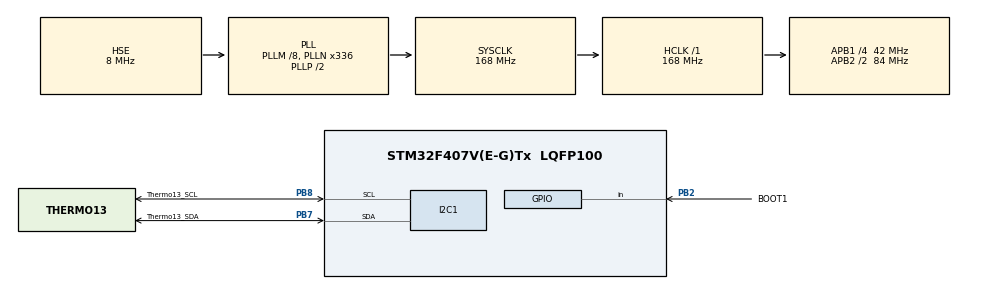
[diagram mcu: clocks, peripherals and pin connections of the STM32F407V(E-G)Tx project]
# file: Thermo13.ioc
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Mcu.Family=STM32F4
Mcu.Name=STM32F407V(E-G)Tx
Mcu.Package=LQFP100
NVIC.I2C1_ER_IRQn=true\:0\:0\:false\:false\:true\:true\:true\:true
NVIC.I2C1_EV_IRQn=true\:0\:0\:false\:false\:true\:true\:true\:true
NVIC.PriorityGroup=NVIC_PRIORITYGROUP_0
PA13.GPIO_Label=SWDIO
PA13.Mode=JTAG_5_pins
PA13.Signal=SYS_JTMS-SWDIO
PA14.GPIO_Label=SWCLK
PA14.Mode=JTAG_5_pins
PA14.Signal=SYS_JTCK-SWCLK
PA15.Mode=JTAG_5_pins
PA15.Signal=SYS_JTDI
PB2.GPIO_Label=BOOT1
PB2.GPIO_Mode=GPIO_MODE_INPUT
PB2.GPIO_PuPd=GPIO_NOPULL
PB2.Signal=GPIO_Input
PB3.Mode=JTAG_5_pins
PB3.Signal=SYS_JTDO-SWO
PB4.Mode=JTAG_5_pins
PB4.Signal=SYS_JTRST
PB7.GPIO_Label=Thermo13_SDA
PB7.Mode=I2C
PB7.Signal=I2C1_SDA
PB8.GPIO_Label=Thermo13_SCL
PB8.Mode=I2C
PB8.Signal=I2C1_SCL
PC14-OSC32_IN.GPIO_Label=PC14-OSC32_IN
PC14-OSC32_IN.Mode=LSE-External-Oscillator
PC14-OSC32_IN.Signal=RCC_OSC32_IN
PC15-OSC32_OUT.GPIO_Label=PC15-OSC32_OUT
PC15-OSC32_OUT.Mode=LSE-External-Oscillator
PC15-OSC32_OUT.Signal=RCC_OSC32_OUT
PH0-OSC_IN.GPIO_Label=PH0-OSC_IN
PH0-OSC_IN.Mode=HSE-External-Oscillator
PH0-OSC_IN.Signal=RCC_OSC_IN
PH1-OSC_OUT.GPIO_Label=PH1-OSC_OUT
PH1-OSC_OUT.Mode=HSE-External-Oscillator
PH1-OSC_OUT.Signal=RCC_OSC_OUT
ProjectManager.HeapSize=0x200
ProjectManager.StackSize=0x400
ProjectManager.TargetToolchain=STM32CubeIDE
RCC.48MHZClocksFreq_Value=48000000
RCC.AHBFreq_Value=168000000
RCC.APB1CLKDivider=RCC_HCLK_DIV4
RCC.APB1Freq_Value=42000000
RCC.APB1TimFreq_Value=84000000
RCC.APB2CLKDivider=RCC_HCLK_DIV2
RCC.APB2Freq_Value=84000000
RCC.APB2TimFreq_Value=168000000
RCC.CortexFreq_Value=168000000
RCC.HCLKFreq_Value=168000000
RCC.HSE_VALUE=8000000
RCC.HSI_VALUE=16000000
RCC.PLLM=8
RCC.PLLN=336
RCC.PLLQ=7
RCC.PLLSourceVirtual=RCC_PLLSOURCE_HSE
RCC.SYSCLKFreq_VALUE=168000000
RCC.SYSCLKSource=RCC_SYSCLKSOURCE_PLLCLK
RCC.VCOOutputFreq_Value=336000000
board=STM32F407G-DISC1

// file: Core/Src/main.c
/* USER CODE BEGIN Header */
/**
  ******************************************************************************
  * @file           : main.c
  * @brief          : Main program body
  ******************************************************************************
  * @attention
  *
  * Copyright (c) 2023 STMicroelectronics.
  * All rights reserved.
  *
  * This software is licensed under terms that can be found in the LICENSE file
  * in the root directory of this software component.
  * If no LICENSE file comes with this software, it is provided AS-IS.
  *
  ******************************************************************************
  */
/* USER CODE END Header */
#include "main.h"

/* USER CODE BEGIN Includes */
#include <stdio.h>
#include <stdint.h>
#include "Thermo13.h"
/* USER CODE END Includes */

/* USER CODE BEGIN PD */
#define THERMO_SLAVE_ADDR (0x48 << 1)
/* USER CODE END PD */

I2C_HandleTypeDef hi2c1;

void SystemClock_Config(void);
static void MX_GPIO_Init(void);
static void MX_I2C1_Init(void);

/* USER CODE BEGIN 0 */
int _write(int file, char *ptr, int len)

{
	int DataIdx;

    for(DataIdx = 0; DataIdx < len; DataIdx++)

    { ITM_SendChar(*ptr++); }

     return len;

}
/* USER CODE END 0 */

int main(void)
{
  /* USER CODE BEGIN 1 */
uint8_t buf[2];
char log[100];;
float temperature;
  /* USER CODE END 1 */

  /* MCU Configuration--------------------------------------------------------*/

  /* Reset of all peripherals, Initializes the Flash interface and the Systick. */
  HAL_Init();

  /* Configure the system clock */
  SystemClock_Config();

  /* Initialize all configured peripherals */
  MX_GPIO_Init();
  MX_I2C1_Init();

  /* Infinite loop */
  /* USER CODE BEGIN WHILE */
  while (1)
  {
	  HAL_I2C_Master_Receive(&hi2c1, THERMO_SLAVE_ADDR, buf, sizeof(buf), HAL_MAX_DELAY);
	  sprintf(log, "I2C Slave Data: 0x%x, 0x%x,\r\n", buf[0], buf[1]);
	  printf(log);
	  log[0] = '\0';
	  temperature = calc_temp(buf);
	  printf("Converted Data\r\n");
	  sprintf(log, " %.1f deg C\r\n",temperature);
	  printf(log);
	  HAL_Delay(1000);
  }

    /* USER CODE END WHILE */

}

void SystemClock_Config(void)
{
  RCC_OscInitTypeDef RCC_OscInitStruct = {0};
  RCC_ClkInitTypeDef RCC_ClkInitStruct = {0};

  /** Configure the main internal regulator output voltage
  */
  __HAL_RCC_PWR_CLK_ENABLE();
  __HAL_PWR_VOLTAGESCALING_CONFIG(PWR_REGULATOR_VOLTAGE_SCALE1);

  /** Initializes the RCC Oscillators according to the specified parameters
  * in the RCC_OscInitTypeDef structure.
  */
  RCC_OscInitStruct.OscillatorType = RCC_OSCILLATORTYPE_HSE;
  RCC_OscInitStruct.HSEState = RCC_HSE_ON;
  RCC_OscInitStruct.PLL.PLLState = RCC_PLL_ON;
  RCC_OscInitStruct.PLL.PLLSource = RCC_PLLSOURCE_HSE;
  RCC_OscInitStruct.PLL.PLLM = 8;
  RCC_OscInitStruct.PLL.PLLN = 336;
  RCC_OscInitStruct.PLL.PLLP = RCC_PLLP_DIV2;
  RCC_OscInitStruct.PLL.PLLQ = 7;
  if (HAL_RCC_OscConfig(&RCC_OscInitStruct) != HAL_OK)
  {
    Error_Handler();
  }

  /** Initializes the CPU, AHB and APB buses clocks
  */
  RCC_ClkInitStruct.ClockType = RCC_CLOCKTYPE_HCLK|RCC_CLOCKTYPE_SYSCLK
                              |RCC_CLOCKTYPE_PCLK1|RCC_CLOCKTYPE_PCLK2;
  RCC_ClkInitStruct.SYSCLKSource = RCC_SYSCLKSOURCE_PLLCLK;
  RCC_ClkInitStruct.AHBCLKDivider = RCC_SYSCLK_DIV1;
  RCC_ClkInitStruct.APB1CLKDivider = RCC_HCLK_DIV4;
  RCC_ClkInitStruct.APB2CLKDivider = RCC_HCLK_DIV2;

  if (HAL_RCC_ClockConfig(&RCC_ClkInitStruct, FLASH_LATENCY_5) != HAL_OK)
  {
    Error_Handler();
  }
}

static void MX_I2C1_Init(void)
{

  hi2c1.Instance = I2C1;
  hi2c1.Init.ClockSpeed = 100000;
  hi2c1.Init.DutyCycle = I2C_DUTYCYCLE_2;
  hi2c1.Init.OwnAddress1 = 0;
  hi2c1.Init.AddressingMode = I2C_ADDRESSINGMODE_7BIT;
  hi2c1.Init.DualAddressMode = I2C_DUALADDRESS_DISABLE;
  hi2c1.Init.OwnAddress2 = 0;
  hi2c1.Init.GeneralCallMode = I2C_GENERALCALL_DISABLE;
  hi2c1.Init.NoStretchMode = I2C_NOSTRETCH_DISABLE;
  if (HAL_I2C_Init(&hi2c1) != HAL_OK)
  {
    Error_Handler();
  }

}

static void MX_GPIO_Init(void)
{
  GPIO_InitTypeDef GPIO_InitStruct = {0};

  /* GPIO Ports Clock Enable */
  __HAL_RCC_GPIOC_CLK_ENABLE();
  __HAL_RCC_GPIOH_CLK_ENABLE();
  __HAL_RCC_GPIOB_CLK_ENABLE();
  __HAL_RCC_GPIOA_CLK_ENABLE();

  /*Configure GPIO pin : BOOT1_Pin */
  GPIO_InitStruct.Pin = BOOT1_Pin;
  GPIO_InitStruct.Mode = GPIO_MODE_INPUT;
  GPIO_InitStruct.Pull = GPIO_NOPULL;
  HAL_GPIO_Init(BOOT1_GPIO_Port, &GPIO_InitStruct);

}

void Error_Handler(void)
{
  __disable_irq();
  while (1)
  {
  }
}
